AUTOSAR XML (schema 00046)
package /ComponentTypes
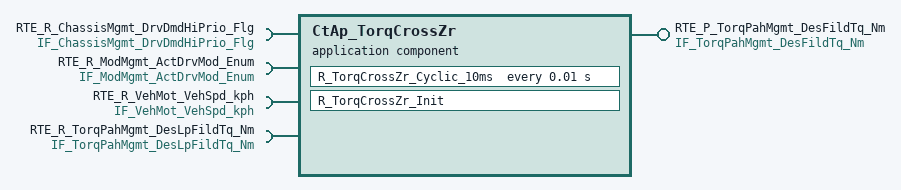
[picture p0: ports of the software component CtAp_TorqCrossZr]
  application sw component type CtAp_TorqCrossZr
    provide port RTE_P_TorqPahMgmt_DesFildTq_Nm: nonqueued-sender-com-spec{data-element=tec_TorqPahMgmt_DesFildTq_Nm, init-value=0}, provided-interface=IF_TorqPahMgmt_DesFildTq_Nm
    4 x require port:
      RTE_R_ChassisMgmt_DrvDmdHiPrio_Flg: nonqueued-receiver-com-spec{data-element=tec_ChassisMgmt_DrvDmdHiPrio_Flg, filter=data-filter-type=ALWAYS, init-value=0}, required-interface=IF_ChassisMgmt_DrvDmdHiPrio_Flg
      RTE_R_ModMgmt_ActDrvMod_Enum: nonqueued-receiver-com-spec{data-element=tec_ModMgmt_ActDrvMod_Enum, filter=data-filter-type=ALWAYS, init-value=0}, required-interface=IF_ModMgmt_ActDrvMod_Enum
      RTE_R_VehMot_VehSpd_kph: nonqueued-receiver-com-spec{data-element=tec_VehMot_VehSpd_kph, filter=data-filter-type=ALWAYS, init-value=0}, required-interface=IF_VehMot_VehSpd_kph
      RTE_R_TorqPahMgmt_DesLpFildTq_Nm: nonqueued-receiver-com-spec{data-element=tec_TorqPahMgmt_DesLpFildTq_Nm, filter=data-filter-type=ALWAYS, init-value=0}, required-interface=IF_TorqPahMgmt_DesLpFildTq_Nm
    behavior CtAp_TorqCrossZr_InternalBehavior
      init event CtAp_TorqCrossZr_InitEvent: start-on-event=R_TorqCrossZr_Init
      timing event TMT_R_TorqCrossZr_Cyclic_10ms: start-on-event=R_TorqCrossZr_Cyclic_10ms, period=0.01
      runnable R_TorqCrossZr_Init
      runnable R_TorqCrossZr_Cyclic_10ms
        data-receive-point-by-arguments:
          4 x access:
            REC_RTE_R_ChassisMgmt_DrvDmdHiPrio_Flg_tec_ChassisMgmt_DrvDmdHiPrio_Flg: accessed-variable=RTE_R_ChassisMgmt_DrvDmdHiPrio_Flg.tec_ChassisMgmt_DrvDmdHiPrio_Flg
            REC_RTE_R_ModMgmt_ActDrvMod_Enum_tec_ModMgmt_ActDrvMod_Enum: accessed-variable=RTE_R_ModMgmt_ActDrvMod_Enum.tec_ModMgmt_ActDrvMod_Enum
            REC_RTE_R_TorqPahMgmt_DesLpFildTq_Nm_tec_TorqPahMgmt_DesLpFildTq_Nm: accessed-variable=RTE_R_TorqPahMgmt_DesLpFildTq_Nm.tec_TorqPahMgmt_DesLpFildTq_Nm
            REC_RTE_R_VehMot_VehSpd_kph_tec_VehMot_VehSpd_kph: accessed-variable=RTE_R_VehMot_VehSpd_kph.tec_VehMot_VehSpd_kph
        data-send-points:
          access SEND_RTE_P_TorqPahMgmt_DesFildTq_Nm_tec_TorqPahMgmt_DesFildTq_Nm: accessed-variable=RTE_P_TorqPahMgmt_DesFildTq_Nm.tec_TorqPahMgmt_DesFildTq_Nm
  swc implementation CtAp_TorqCrossZr_Implementation: behavior=CtAp_TorqCrossZr_InternalBehavior
    code-descriptors:
      code Default: artifact-descriptors=autosar-engineering-object=category=SWOBJ
